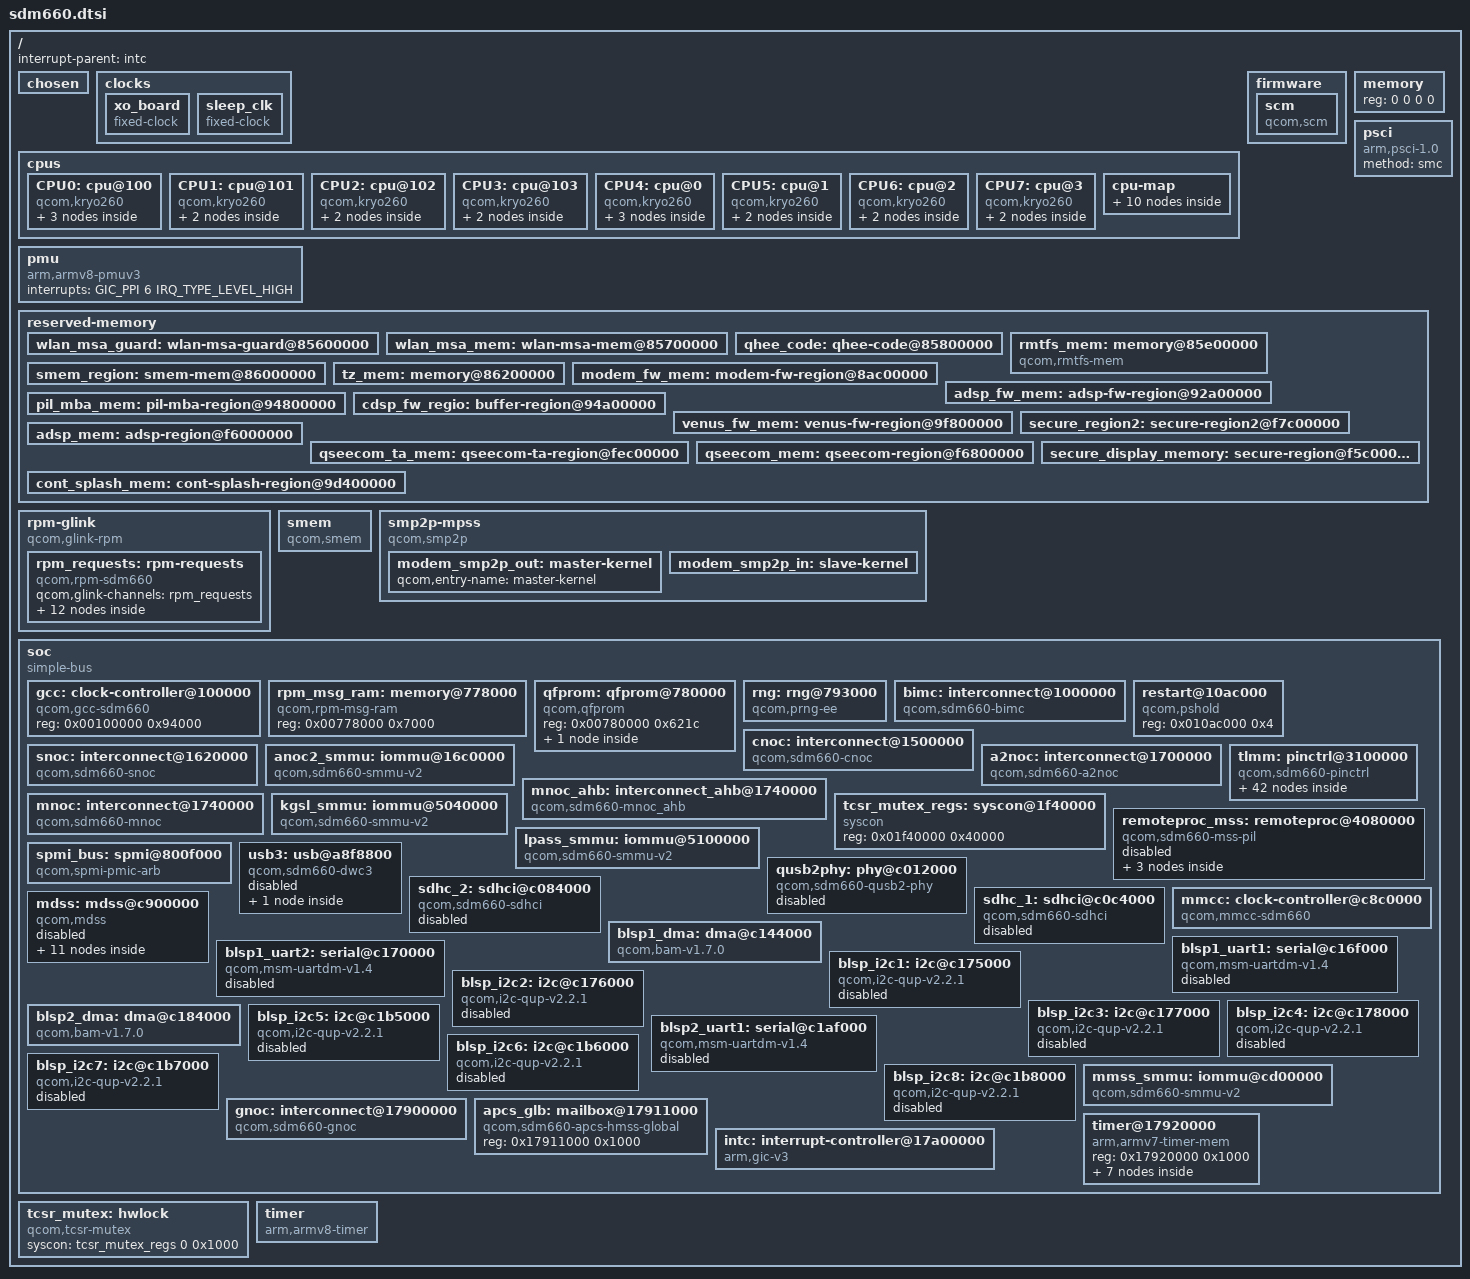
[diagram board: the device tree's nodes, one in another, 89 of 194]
// SPDX-License-Identifier: GPL-2.0-only
/*
 * Copyright (c) 2018, Craig Tatlor.
 * Copyright (c) 2020, Alexey Minnekhanov <alexey.min@gmail.com>
 */

#include <dt-bindings/clock/qcom,gcc-sdm660.h>
#include <dt-bindings/clock/qcom,mmcc-sdm660.h>
#include <dt-bindings/clock/qcom,rpmcc.h>
#include <dt-bindings/power/qcom-rpmpd.h>
#include <dt-bindings/gpio/gpio.h>
#include <dt-bindings/interconnect/qcom,sdm660.h>
#include <dt-bindings/interrupt-controller/arm-gic.h>

/ {
	interrupt-parent = <&intc>;

	#address-cells = <2>;
	#size-cells = <2>;

	chosen { };

	clocks {
		xo_board: xo_board {
			compatible = "fixed-clock";
			#clock-cells = <0>;
			clock-frequency = <19200000>;
			clock-output-names = "xo_board";
		};

		sleep_clk: sleep_clk {
			compatible = "fixed-clock";
			#clock-cells = <0>;
			clock-frequency = <32764>;
			clock-output-names = "sleep_clk";
		};
	};

	cpus {
		#address-cells = <2>;
		#size-cells = <0>;

		CPU0: cpu@100 {
			device_type = "cpu";
			compatible = "qcom,kryo260";
			reg = <0x0 0x100>;
			enable-method = "psci";
			capacity-dmips-mhz = <1024>;
			next-level-cache = <&L2_1>;
			L2_1: l2-cache {
				compatible = "cache";
				cache-level = <2>;
			};
			L1_I_100: l1-icache {
				compatible = "cache";
			};
			L1_D_100: l1-dcache {
				compatible = "cache";
			};
		};

		CPU1: cpu@101 {
			device_type = "cpu";
			compatible = "qcom,kryo260";
			reg = <0x0 0x101>;
			enable-method = "psci";
			capacity-dmips-mhz = <1024>;
			next-level-cache = <&L2_1>;
			L1_I_101: l1-icache {
				compatible = "cache";
			};
			L1_D_101: l1-dcache {
				compatible = "cache";
			};
		};

		CPU2: cpu@102 {
			device_type = "cpu";
			compatible = "qcom,kryo260";
			reg = <0x0 0x102>;
			enable-method = "psci";
			capacity-dmips-mhz = <1024>;
			next-level-cache = <&L2_1>;
			L1_I_102: l1-icache {
				compatible = "cache";
			};
			L1_D_102: l1-dcache {
				compatible = "cache";
			};
		};

		CPU3: cpu@103 {
			device_type = "cpu";
			compatible = "qcom,kryo260";
			reg = <0x0 0x103>;
			enable-method = "psci";
			capacity-dmips-mhz = <1024>;
			next-level-cache = <&L2_1>;
			L1_I_103: l1-icache {
				compatible = "cache";
			};
			L1_D_103: l1-dcache {
				compatible = "cache";
			};
		};

		CPU4: cpu@0 {
			device_type = "cpu";
			compatible = "qcom,kryo260";
			reg = <0x0 0x0>;
			enable-method = "psci";
			capacity-dmips-mhz = <640>;
			next-level-cache = <&L2_0>;
			L2_0: l2-cache {
				compatible = "cache";
				cache-level = <2>;
			};
			L1_I_0: l1-icache {
				compatible = "cache";
			};
			L1_D_0: l1-dcache {
				compatible = "cache";
			};
		};

		CPU5: cpu@1 {
			device_type = "cpu";
			compatible = "qcom,kryo260";
			reg = <0x0 0x1>;
			enable-method = "psci";
			capacity-dmips-mhz = <640>;
			next-level-cache = <&L2_0>;
			L1_I_1: l1-icache {
				compatible = "cache";
			};
			L1_D_1: l1-dcache {
				compatible = "cache";
			};
		};

		CPU6: cpu@2 {
			device_type = "cpu";
			compatible = "qcom,kryo260";
			reg = <0x0 0x2>;
			enable-method = "psci";
			capacity-dmips-mhz = <640>;
			next-level-cache = <&L2_0>;
			L1_I_2: l1-icache {
				compatible = "cache";
			};
			L1_D_2: l1-dcache {
				compatible = "cache";
			};
		};

		CPU7: cpu@3 {
			device_type = "cpu";
			compatible = "qcom,kryo260";
			reg = <0x0 0x3>;
			enable-method = "psci";
			capacity-dmips-mhz = <640>;
			next-level-cache = <&L2_0>;
			L1_I_3: l1-icache {
				compatible = "cache";
			};
			L1_D_3: l1-dcache {
				compatible = "cache";
			};
		};

		cpu-map {
			cluster0 {
				core0 {
					cpu = <&CPU4>;
				};

				core1 {
					cpu = <&CPU5>;
				};

				core2 {
					cpu = <&CPU6>;
				};

				core3 {
					cpu = <&CPU7>;
				};
			};

			cluster1 {
				core0 {
					cpu = <&CPU0>;
				};

				core1 {
					cpu = <&CPU1>;
				};

				core2 {
					cpu = <&CPU2>;
				};

				core3 {
					cpu = <&CPU3>;
				};
			};
		};
	};

	firmware {
		scm {
			compatible = "qcom,scm";
		};
	};

	memory {
		device_type = "memory";
		/* We expect the bootloader to fill in the reg */
		reg = <0 0 0 0>;
	};

	pmu {
		compatible = "arm,armv8-pmuv3";
		interrupts = <GIC_PPI 6 IRQ_TYPE_LEVEL_HIGH>;
	};

	psci {
		compatible = "arm,psci-1.0";
		method = "smc";
	};

	reserved-memory {
		#address-cells = <2>;
		#size-cells = <2>;
		ranges;

		wlan_msa_guard: wlan-msa-guard@85600000 {
			reg = <0x0 0x85600000 0x0 0x100000>;
			no-map;
		};

		wlan_msa_mem: wlan-msa-mem@85700000 {
			reg = <0x0 0x85700000 0x0 0x100000>;
			no-map;
		};

		qhee_code: qhee-code@85800000 {
			reg = <0x0 0x85800000 0x0 0x3700000>;
			no-map;
		};

		rmtfs_mem: memory@85e00000 {
			compatible = "qcom,rmtfs-mem";
			reg = <0x0 0x85e00000 0x0 0x200000>;
			no-map;

			qcom,client-id = <1>;
			qcom,vmid = <15>;
		};

		smem_region: smem-mem@86000000 {
			reg = <0 0x86000000 0 0x200000>;
			no-map;
		};

		tz_mem: memory@86200000 {
			reg = <0x0 0x86200000 0x0 0x3300000>;
			no-map;
		};

		modem_fw_mem: modem-fw-region@8ac00000 {
			reg = <0x0 0x8ac00000 0x0 0x7e00000>;
			no-map;
		};

		adsp_fw_mem: adsp-fw-region@92a00000 {
			reg = <0x0 0x92a00000 0x0 0x1e00000>;
			no-map;
		};

		pil_mba_mem: pil-mba-region@94800000 {
			reg = <0x0 0x94800000 0x0 0x200000>;
			no-map;
		};

		cdsp_fw_regio: buffer-region@94a00000 {
			reg = <0x0 0x94a00000 0x0 0x100000>;
			no-map;
		};

		venus_fw_mem: venus-fw-region@9f800000 {
			reg = <0x0 0x9f800000 0x0 0x800000>;
			no-map;
		};

		secure_region2: secure-region2@f7c00000 {
			reg = <0x0 0xf7c00000 0x0 0x5c00000>;
			no-map;
		};

		adsp_mem: adsp-region@f6000000 {
			reg = <0x0 0xf6000000 0x0 0x800000>;
			no-map;
		};

		qseecom_ta_mem: qseecom-ta-region@fec00000 {
			reg = <0x0 0xfec00000 0x0 0x1000000>;
			no-map;
		};

		qseecom_mem: qseecom-region@f6800000 {
			reg = <0x0 0xf6800000 0x0 0x1400000>;
			no-map;
		};

		secure_display_memory: secure-region@f5c00000 {
			reg = <0x0 0xf5c00000 0x0 0x5c00000>;
			no-map;
		};

		cont_splash_mem: cont-splash-region@9d400000 {
			reg = <0x0 0x9d400000 0x0 0x23ff000>;
			no-map;
		};
	};

	rpm-glink {
		compatible = "qcom,glink-rpm";

		interrupts = <GIC_SPI 168 IRQ_TYPE_EDGE_RISING>;
		qcom,rpm-msg-ram = <&rpm_msg_ram>;
		mboxes = <&apcs_glb 0>;

		rpm_requests: rpm-requests {
			compatible = "qcom,rpm-sdm660";
			qcom,glink-channels = "rpm_requests";

			rpmcc: clock-controller {
				compatible = "qcom,rpmcc-sdm660", "qcom,rpmcc";
				#clock-cells = <1>;
			};

			rpmpd: power-controller {
				compatible = "qcom,sdm660-rpmpd";
				#power-domain-cells = <1>;
				operating-points-v2 = <&rpmpd_opp_table>;

				rpmpd_opp_table: opp-table {
					compatible = "operating-points-v2";

					rpmpd_opp_ret: opp1 {
						opp-level = <16>;
					};

					rpmpd_opp_ret_plus: opp2 {
						opp-level = <32>;
					};

					rpmpd_opp_min_svs: opp3 {
						opp-level = <48>;
					};

					rpmpd_opp_low_svs: opp4 {
						opp-level = <64>;
					};

					rpmpd_opp_svs: opp5 {
						opp-level = <128>;
					};

					rpmpd_opp_svs_plus: opp6 {
						opp-level = <192>;
					};

					rpmpd_opp_nom: opp7 {
						opp-level = <256>;
					};

					rpmpd_opp_nom_plus: opp8 {
						opp-level = <320>;
					};

					rpmpd_opp_turbo: opp9 {
						opp-level = <384>;
					};
				};
			};
		};
	};

	smem: smem {
		compatible = "qcom,smem";
		memory-region = <&smem_region>;
		hwlocks = <&tcsr_mutex 3>;
	};

	smp2p-mpss {
		compatible = "qcom,smp2p";
		qcom,smem = <435>, <428>;
		interrupts = <GIC_SPI 451 IRQ_TYPE_EDGE_RISING>;
		mboxes = <&apcs_glb 14>;
		qcom,local-pid = <0>;
		qcom,remote-pid = <1>;

		modem_smp2p_out: master-kernel {
			qcom,entry-name = "master-kernel";
			#qcom,smem-state-cells = <1>;
		};

		modem_smp2p_in: slave-kernel {
			qcom,entry-name = "slave-kernel";
			interrupt-controller;
			#interrupt-cells = <2>;
		};
	};

	soc: soc {
		#address-cells = <1>;
		#size-cells = <1>;
		ranges = <0 0 0 0xffffffff>;
		compatible = "simple-bus";

		gcc: clock-controller@100000 {
			compatible = "qcom,gcc-sdm660";
			#clock-cells = <1>;
			#reset-cells = <1>;
			#power-domain-cells = <1>;
			reg = <0x00100000 0x94000>;
		};

		rpm_msg_ram: memory@778000 {
			compatible = "qcom,rpm-msg-ram";
			reg = <0x00778000 0x7000>;
		};

		qfprom: qfprom@780000 {
			compatible = "qcom,qfprom";
			reg = <0x00780000 0x621c>;
			#address-cells = <1>;
			#size-cells = <1>;

			qusb2_hstx_trim: hstx-trim@240 {
				reg = <0x240 0x1>;
				bits = <0 4>;
			};
		};

		rng: rng@793000 {
			compatible = "qcom,prng-ee";
			reg = <0x00793000 0x1000>;
			clocks = <&gcc GCC_PRNG_AHB_CLK>;
			clock-names = "core";
		};

		bimc: interconnect@1000000 {
			compatible = "qcom,sdm660-bimc";
			reg = <0x01000000 0x80000>;
			#interconnect-cells = <1>;
			clock-names = "bus", "bus_a";
			clocks = <&rpmcc RPM_SMD_BIMC_CLK>,
				 <&rpmcc RPM_SMD_BIMC_A_CLK>;
		};

		restart@10ac000 {
			compatible = "qcom,pshold";
			reg = <0x010ac000 0x4>;
		};

		cnoc: interconnect@1500000 {
			compatible = "qcom,sdm660-cnoc";
			reg = <0x01500000 0x10000>;
			#interconnect-cells = <1>;
			clock-names = "bus", "bus_a";
			clocks = <&rpmcc RPM_SMD_CNOC_CLK>,
				 <&rpmcc RPM_SMD_CNOC_A_CLK>;
		};

		snoc: interconnect@1620000 {
			compatible = "qcom,sdm660-snoc";
			reg = <0x01620000 0x20000>;
			#interconnect-cells = <1>;
			clock-names = "bus", "bus_a";
			clocks = <&rpmcc RPM_SMD_SNOC_CLK>,
				 <&rpmcc RPM_SMD_SNOC_A_CLK>;
		};

		anoc2_smmu: iommu@16c0000 {
			compatible = "qcom,sdm660-smmu-v2", "qcom,smmu-v2";
			reg = <0x016c0000 0x40000>;
			#iommu-cells = <1>;
			qcom,use-3-lvl-tables;
			qcom,skip-init;

			#global-interrupts = <2>;
			interrupts =
				<GIC_SPI 229 IRQ_TYPE_LEVEL_HIGH>,
				<GIC_SPI 231 IRQ_TYPE_LEVEL_HIGH>,

				<GIC_SPI 373 IRQ_TYPE_LEVEL_HIGH>,
				<GIC_SPI 374 IRQ_TYPE_LEVEL_LOW>,
				<GIC_SPI 375 IRQ_TYPE_LEVEL_LOW>,
				<GIC_SPI 376 IRQ_TYPE_LEVEL_LOW>,
				<GIC_SPI 377 IRQ_TYPE_LEVEL_LOW>,
				<GIC_SPI 378 IRQ_TYPE_LEVEL_LOW>,
				<GIC_SPI 462 IRQ_TYPE_LEVEL_HIGH>,
				<GIC_SPI 463 IRQ_TYPE_LEVEL_HIGH>,
				<GIC_SPI 464 IRQ_TYPE_LEVEL_HIGH>,
				<GIC_SPI 465 IRQ_TYPE_LEVEL_HIGH>,
				<GIC_SPI 466 IRQ_TYPE_LEVEL_HIGH>,
				<GIC_SPI 467 IRQ_TYPE_LEVEL_HIGH>,
				<GIC_SPI 353 IRQ_TYPE_LEVEL_HIGH>,
				<GIC_SPI 354 IRQ_TYPE_LEVEL_HIGH>,
				<GIC_SPI 355 IRQ_TYPE_LEVEL_HIGH>,
				<GIC_SPI 356 IRQ_TYPE_LEVEL_HIGH>,
				<GIC_SPI 357 IRQ_TYPE_LEVEL_HIGH>,
				<GIC_SPI 358 IRQ_TYPE_LEVEL_HIGH>,
				<GIC_SPI 359 IRQ_TYPE_LEVEL_HIGH>,
				<GIC_SPI 360 IRQ_TYPE_LEVEL_HIGH>,
				<GIC_SPI 442 IRQ_TYPE_LEVEL_HIGH>,
				<GIC_SPI 443 IRQ_TYPE_LEVEL_HIGH>,
				<GIC_SPI 444 IRQ_TYPE_LEVEL_HIGH>,
				<GIC_SPI 447 IRQ_TYPE_LEVEL_HIGH>,
				<GIC_SPI 468 IRQ_TYPE_LEVEL_HIGH>,
				<GIC_SPI 469 IRQ_TYPE_LEVEL_HIGH>,
				<GIC_SPI 472 IRQ_TYPE_LEVEL_HIGH>,
				<GIC_SPI 473 IRQ_TYPE_LEVEL_HIGH>,
				<GIC_SPI 474 IRQ_TYPE_LEVEL_HIGH>;
		};

		a2noc: interconnect@1700000 {
			compatible = "qcom,sdm660-a2noc";
			reg = <0x01700000 0x20000>;
			#interconnect-cells = <1>;
			clock-names = "bus", "bus_a";
			clocks = <&rpmcc RPM_SMD_AGGR2_NOC_CLK>,
				 <&rpmcc RPM_SMD_AGGR2_NOC_A_CLK>;
		};

		/*
		 * Having two nodes at the same address with the
		 * same name isn't something DTC agrees with..
		 */
		mnoc_ahb: interconnect_ahb@1740000 {
			compatible = "qcom,sdm660-mnoc_ahb";
			reg = <0x01740000 0x10000>;
			#interconnect-cells = <1>;
			clock-names = "bus", "bus_a";
			clocks = <&mmcc AHB_CLK_SRC>, <&mmcc AHB_CLK_SRC>;
		};

		mnoc: interconnect@1740000 {
			compatible = "qcom,sdm660-mnoc";
			reg = <0x01740000 0x10000>;
			#interconnect-cells = <1>;
			clock-names = "bus", "bus_a";
			clocks = <&rpmcc RPM_SMD_MMSSNOC_AXI_CLK>,
				 <&rpmcc RPM_SMD_MMSSNOC_AXI_CLK_A>;
		};

		tcsr_mutex_regs: syscon@1f40000 {
			compatible = "syscon";
			reg = <0x01f40000 0x40000>;
		};

		tlmm: pinctrl@3100000 {
			compatible = "qcom,sdm660-pinctrl";
			reg = <0x03100000 0x400000>,
			      <0x03500000 0x400000>,
			      <0x03900000 0x400000>;
			reg-names = "south", "center", "north";
			interrupts = <GIC_SPI 208 IRQ_TYPE_LEVEL_HIGH>;
			gpio-controller;
			gpio-ranges = <&tlmm 0 0 114>;
			#gpio-cells = <2>;
			interrupt-controller;
			#interrupt-cells = <2>;

			uart_console_active: uart_console_active {
				pinmux {
					pins = "gpio4", "gpio5";
					function = "blsp_uart2";
				};

				pinconf {
					pins = "gpio4", "gpio5";
					drive-strength = <2>;
					bias-disable;
				};
			};

			blsp1_uart1_default: blsp1-uart1-default {
				pins = "gpio0", "gpio1", "gpio2", "gpio3";
				drive-strength = <2>;
				bias-disable;
			};

			blsp1_uart1_sleep: blsp1-uart1-sleep {
				pins = "gpio0", "gpio1", "gpio2", "gpio3";
				drive-strength = <2>;
				bias-disable;
			};

			blsp1_uart2_default: blsp1-uart2-default {
				pins = "gpio4", "gpio5";
				drive-strength = <2>;
				bias-disable;
			};

			blsp2_uart1_tx_active: blsp2-uart1-tx-active {
				pins = "gpio16";
				drive-strength = <2>;
				bias-disable;
			};

			blsp2_uart1_tx_sleep: blsp2-uart1-tx-sleep {
				pins = "gpio16";
				drive-strength = <2>;
				bias-pull-up;
			};

			blsp2_uart1_rxcts_active: blsp2-uart1-rxcts-active {
				pins = "gpio17", "gpio18";
				drive-strength = <2>;
				bias-disable;
			};

			blsp2_uart1_rxcts_sleep: blsp2-uart1-rxcts-sleep {
				pins = "gpio17", "gpio18";
				drive-strength = <2>;
				bias-no-pull;
			};

			blsp2_uart1_rfr_active: blsp2-uart1-rfr-active {
				pins = "gpio19";
				drive-strength = <2>;
				bias-disable;
			};

			blsp2_uart1_rfr_sleep: blsp2-uart1-rfr-sleep {
				pins = "gpio19";
				drive-strength = <2>;
				bias-no-pull;
			};

			i2c1_default: i2c1-default {
				pins = "gpio2", "gpio3";
				drive-strength = <2>;
				bias-disable;
			};

			i2c1_sleep: i2c1-sleep {
				pins = "gpio2", "gpio3";
				drive-strength = <2>;
				bias-pull-up;
			};

			i2c2_default: i2c2-default {
				pins = "gpio6", "gpio7";
				drive-strength = <2>;
				bias-disable;
			};

			i2c2_sleep: i2c2-sleep {
				pins = "gpio6", "gpio7";
				drive-strength = <2>;
				bias-pull-up;
			};

			i2c3_default: i2c3-default {
				pins = "gpio10", "gpio11";
				drive-strength = <2>;
				bias-disable;
			};

			i2c3_sleep: i2c3-sleep {
				pins = "gpio10", "gpio11";
				drive-strength = <2>;
				bias-pull-up;
			};

			i2c4_default: i2c4-default {
				pins = "gpio14", "gpio15";
				drive-strength = <2>;
				bias-disable;
			};

			i2c4_sleep: i2c4-sleep {
				pins = "gpio14", "gpio15";
				drive-strength = <2>;
				bias-pull-up;
			};

			i2c5_default: i2c5-default {
				pins = "gpio18", "gpio19";
				drive-strength = <2>;
				bias-disable;
			};

			i2c5_sleep: i2c5-sleep {
				pins = "gpio18", "gpio19";
				drive-strength = <2>;
				bias-pull-up;
			};

			i2c6_default: i2c6-default {
				pins = "gpio22", "gpio23";
				drive-strength = <2>;
				bias-disable;
			};

			i2c6_sleep: i2c6-sleep {
				pins = "gpio22", "gpio23";
				drive-strength = <2>;
				bias-pull-up;
			};

			i2c7_default: i2c7-default {
				pins = "gpio26", "gpio27";
				drive-strength = <2>;
				bias-disable;
			};

			i2c7_sleep: i2c7-sleep {
				pins = "gpio26", "gpio27";
				drive-strength = <2>;
				bias-pull-up;
			};

			i2c8_default: i2c8-default {
				pins = "gpio30", "gpio31";
				drive-strength = <2>;
				bias-disable;
			};

			i2c8_sleep: i2c8-sleep {
				pins = "gpio30", "gpio31";
				drive-strength = <2>;
				bias-pull-up;
			};

			sdc1_clk_on: sdc1-clk-on {
				pins = "sdc1_clk";
				bias-disable;
				drive-strength = <16>;
			};

			sdc1_clk_off: sdc1-clk-off {
				pins = "sdc1_clk";
				bias-disable;
				drive-strength = <2>;
			};

			sdc1_cmd_on: sdc1-cmd-on {
				pins = "sdc1_cmd";
				bias-pull-up;
				drive-strength = <10>;
			};

			sdc1_cmd_off: sdc1-cmd-off {
				pins = "sdc1_cmd";
				bias-pull-up;
				drive-strength = <2>;
			};

			sdc1_data_on: sdc1-data-on {
				pins = "sdc1_data";
				bias-pull-up;
				drive-strength = <8>;
			};

			sdc1_data_off: sdc1-data-off {
				pins = "sdc1_data";
				bias-pull-up;
				drive-strength = <2>;
			};

			sdc1_rclk_on: sdc1-rclk-on {
				pins = "sdc1_rclk";
				bias-pull-down;
			};

			sdc1_rclk_off: sdc1-rclk-off {
				pins = "sdc1_rclk";
				bias-pull-down;
			};

			sdc2_clk_on: sdc2-clk-on {
				pins = "sdc2_clk";
				bias-disable;
				drive-strength = <16>;
			};

			sdc2_clk_off: sdc2-clk-off {
				pins = "sdc2_clk";
				bias-disable;
				drive-strength = <2>;
			};

			sdc2_cmd_on: sdc2-cmd-on {
				pins = "sdc2_cmd";
				bias-pull-up;
				drive-strength = <10>;
			};

			sdc2_cmd_off: sdc2-cmd-off {
				pins = "sdc2_cmd";
				bias-pull-up;
				drive-strength = <2>;
			};

			sdc2_data_on: sdc2-data-on {
				pins = "sdc2_data";
				bias-pull-up;
				drive-strength = <10>;
			};

			sdc2_data_off: sdc2-data-off {
				pins = "sdc2_data";
				bias-pull-up;
				drive-strength = <2>;
			};
		};

		remoteproc_mss: remoteproc@4080000 {
			compatible = "qcom,sdm660-mss-pil";
			reg = <0x04080000 0x100>, <0x04180000 0x40>;
			reg-names = "qdsp6", "rmb";
			status = "disabled";

			interrupts-extended =
				<&intc GIC_SPI 448 IRQ_TYPE_EDGE_RISING>,
				<&modem_smp2p_in 0 IRQ_TYPE_EDGE_RISING>,
				<&modem_smp2p_in 1 IRQ_TYPE_EDGE_RISING>,
				<&modem_smp2p_in 2 IRQ_TYPE_EDGE_RISING>,
				<&modem_smp2p_in 3 IRQ_TYPE_EDGE_RISING>,
				<&modem_smp2p_in 7 IRQ_TYPE_EDGE_RISING>;
			interrupt-names = "wdog", "fatal", "ready",
					  "handover", "stop-ack",
					  "shutdown-ack";

			clocks = <&gcc GCC_MSS_CFG_AHB_CLK>,
				 <&gcc GCC_BIMC_MSS_Q6_AXI_CLK>,
				 <&gcc GCC_BOOT_ROM_AHB_CLK>,
				 <&gcc GPLL0_OUT_MSSCC>,
				 <&gcc GCC_MSS_SNOC_AXI_CLK>,
				 <&gcc GCC_MSS_MNOC_BIMC_AXI_CLK>,
				 <&rpmcc RPM_SMD_QDSS_CLK>,
				 <&rpmcc RPM_SMD_XO_CLK_SRC>;
			clock-names = "iface", "bus", "mem", "gpll0_mss",
				      "snoc_axi", "mnoc_axi", "qdss", "xo";

			qcom,smem-states = <&modem_smp2p_out 0>;
			qcom,smem-state-names = "stop";

			resets = <&gcc GCC_MSS_RESTART>;
			reset-names = "mss_restart";

			qcom,halt-regs = <&tcsr_mutex_regs 0x23000 0x25000 0x24000>;

			power-domains = <&rpmpd SDM660_VDDCX>,
					<&rpmpd SDM660_VDDMX>;
			power-domain-names = "cx", "mx";

			mba {
				memory-region = <&pil_mba_mem>;
			};

			mpss {
				memory-region = <&modem_fw_mem>;
			};

			glink-edge {
				interrupts = <GIC_SPI 452 IRQ_TYPE_EDGE_RISING>;
				label = "modem";
				qcom,remote-pid = <1>;
				mboxes = <&apcs_glb 15>;
			};
		};

		kgsl_smmu: iommu@5040000 {
			compatible = "qcom,sdm660-smmu-v2", "qcom,smmu-v2";
			reg = <0x05040000 0x10000>;
			#iommu-cells = <1>;
			qcom,use-3-lvl-tables;
			qcom,skip-init;

			interrupts =
				<GIC_SPI 329 IRQ_TYPE_LEVEL_HIGH>,
				<GIC_SPI 330 IRQ_TYPE_LEVEL_HIGH>,
				<GIC_SPI 331 IRQ_TYPE_LEVEL_HIGH>,
				<GIC_SPI 332 IRQ_TYPE_LEVEL_HIGH>,
				<GIC_SPI 116 IRQ_TYPE_LEVEL_HIGH>;
		};

		lpass_smmu: iommu@5100000 {
			compatible = "qcom,sdm660-smmu-v2", "qcom,smmu-v2";
			reg = <0x05100000 0x40000>;
			#iommu-cells = <1>;
			qcom,use-3-lvl-tables;
			qcom,skip-init;

			#global-interrupts = <2>;
			interrupts =
				<GIC_SPI 229 IRQ_TYPE_LEVEL_HIGH>,
				<GIC_SPI 231 IRQ_TYPE_LEVEL_HIGH>,

				<GIC_SPI 226 IRQ_TYPE_LEVEL_HIGH>,
				<GIC_SPI 393 IRQ_TYPE_LEVEL_HIGH>,
				<GIC_SPI 394 IRQ_TYPE_LEVEL_HIGH>,
				<GIC_SPI 395 IRQ_TYPE_LEVEL_HIGH>,
				<GIC_SPI 396 IRQ_TYPE_LEVEL_HIGH>,
				<GIC_SPI 397 IRQ_TYPE_LEVEL_HIGH>,
				<GIC_SPI 398 IRQ_TYPE_LEVEL_HIGH>,
				<GIC_SPI 399 IRQ_TYPE_LEVEL_HIGH>,
				<GIC_SPI 400 IRQ_TYPE_LEVEL_HIGH>,
				<GIC_SPI 401 IRQ_TYPE_LEVEL_HIGH>,
				<GIC_SPI 402 IRQ_TYPE_LEVEL_HIGH>,
				<GIC_SPI 403 IRQ_TYPE_LEVEL_HIGH>,
				<GIC_SPI 137 IRQ_TYPE_LEVEL_HIGH>,
				<GIC_SPI 224 IRQ_TYPE_LEVEL_HIGH>,
				<GIC_SPI 225 IRQ_TYPE_LEVEL_HIGH>,
				<GIC_SPI 310 IRQ_TYPE_LEVEL_HIGH>,
				<GIC_SPI 404 IRQ_TYPE_LEVEL_HIGH>;
		};

		spmi_bus: spmi@800f000 {
			compatible = "qcom,spmi-pmic-arb";
			reg = <0x0800f000 0x1000>,
			      <0x08400000 0x1000000>,
			      <0x09400000 0x1000000>,
			      <0x0a400000 0x220000>,
			      <0x0800a000 0x3000>;
			reg-names = "core", "chnls", "obsrvr", "intr", "cnfg";
			interrupt-names = "periph_irq";
			interrupts = <GIC_SPI 326 IRQ_TYPE_LEVEL_HIGH>;
			qcom,ee = <0>;
			qcom,channel = <0>;
			#address-cells = <2>;
			#size-cells = <0>;
			interrupt-controller;
			#interrupt-cells = <4>;
			cell-index = <0>;
		};

		usb3: usb@a8f8800 {
			compatible = "qcom,sdm660-dwc3", "qcom,dwc3";
			reg = <0x0a8f8800 0x400>;
			status = "disabled";
			#address-cells = <1>;
			#size-cells = <1>;
			ranges;

			clocks = <&gcc GCC_CFG_NOC_USB3_AXI_CLK>,
				 <&gcc GCC_USB30_MASTER_CLK>,
				 <&gcc GCC_AGGRE2_USB3_AXI_CLK>,
				 <&gcc GCC_USB30_MOCK_UTMI_CLK>,
				 <&gcc GCC_USB30_SLEEP_CLK>;
			clock-names = "cfg_noc", "core", "iface", "mock_utmi",
				      "sleep";

			assigned-clocks = <&gcc GCC_USB30_MOCK_UTMI_CLK>,
					  <&gcc GCC_USB30_MASTER_CLK>;
			assigned-clock-rates = <19200000>, <120000000>;

			interrupts = <GIC_SPI 347 IRQ_TYPE_LEVEL_HIGH>,
				     <GIC_SPI 243 IRQ_TYPE_LEVEL_HIGH>;
			interrupt-names = "hs_phy_irq", "ss_phy_irq";

			power-domains = <&gcc USB_30_GDSC>;
			qcom,select-utmi-as-pipe-clk;

			resets = <&gcc GCC_USB_30_BCR>;

			usb3_dwc3: dwc3@a800000 {
				compatible = "snps,dwc3";
				reg = <0x0a800000 0xc8d0>;
				interrupts = <GIC_SPI 131 IRQ_TYPE_LEVEL_HIGH>;
				snps,dis_u2_susphy_quirk;
				snps,dis_enblslpm_quirk;

				/*
				 * SDM660 technically supports USB3 but I
				 * haven't seen any devices making use of it.
				 */
				maximum-speed = "high-speed";
				phys = <&qusb2phy>;
				phy-names = "usb2-phy";
				snps,hird-threshold = /bits/ 8 <0>;
			};
		};

		qusb2phy: phy@c012000 {
			compatible = "qcom,sdm660-qusb2-phy";
			reg = <0x0c012000 0x180>;
			#phy-cells = <0>;

			clocks = <&gcc GCC_USB_PHY_CFG_AHB2PHY_CLK>,
				<&gcc GCC_RX1_USB2_CLKREF_CLK>;
			clock-names = "cfg_ahb", "ref";

			resets = <&gcc GCC_QUSB2PHY_PRIM_BCR>;
			nvmem-cells = <&qusb2_hstx_trim>;
			status = "disabled";
		};

		sdhc_2: sdhci@c084000 {
			compatible = "qcom,sdm660-sdhci", "qcom,sdhci-msm-v5";
			reg = <0x0c084000 0x1000>;
			reg-names = "hc";

			interrupts = <GIC_SPI 125 IRQ_TYPE_LEVEL_HIGH>,
					<GIC_SPI 221 IRQ_TYPE_LEVEL_HIGH>;
			interrupt-names = "hc_irq", "pwr_irq";

			clocks = <&gcc GCC_SDCC2_APPS_CLK>,
					<&gcc GCC_SDCC2_AHB_CLK>,
					<&xo_board>;
			clock-names = "core", "iface", "xo";

			pinctrl-names = "default", "sleep";
			pinctrl-0 = <&sdc2_clk_on &sdc2_cmd_on &sdc2_data_on>;
			pinctrl-1 = <&sdc2_clk_off &sdc2_cmd_off &sdc2_data_off>;

			bus-width = <4>;
			interconnects = <&a2noc MASTER_SDCC_2 &bimc SLAVE_EBI>,
				<&gnoc MASTER_APSS_PROC  &cnoc SLAVE_SDCC_2>;

			status = "disabled";
		};

		sdhc_1: sdhci@c0c4000 {
			compatible = "qcom,sdm660-sdhci", "qcom,sdhci-msm-v5";
			reg = <0x0c0c4000 0x1000>,
				<0x0c0c5000 0x1000>;
			reg-names = "hc", "cqhci";

			interrupts = <GIC_SPI 110 IRQ_TYPE_LEVEL_HIGH>,
					<GIC_SPI 112 IRQ_TYPE_LEVEL_HIGH>;
			interrupt-names = "hc_irq", "pwr_irq";

			clocks = <&gcc GCC_SDCC1_APPS_CLK>,
					<&gcc GCC_SDCC1_AHB_CLK>,
					<&xo_board>;
			clock-names = "core", "iface", "xo";

			pinctrl-names = "default", "sleep";
			pinctrl-0 = <&sdc1_clk_on &sdc1_cmd_on &sdc1_data_on &sdc1_rclk_on>;
			pinctrl-1 = <&sdc1_clk_off &sdc1_cmd_off &sdc1_data_off &sdc1_rclk_off>;

			bus-width = <8>;
			non-removable;

			status = "disabled";
		};

		mmcc: clock-controller@c8c0000 {
			compatible = "qcom,mmcc-sdm660";
			reg = <0x0c8c0000 0x40000>;
			#clock-cells = <1>;
			#reset-cells = <1>;
			#power-domain-cells = <1>;
			clock-names = "xo",
					"sleep_clk",
					"gpll0",
					"gpll0_div",
					"dsi0pll",
					"dsi0pllbyte",
					"dsi1pll",
					"dsi1pllbyte",
					"dp_link_2x_clk_divsel_five",
					"dp_vco_divided_clk_src_mux";
			clocks = <&rpmcc RPM_SMD_XO_CLK_SRC>,
					<&sleep_clk>,
					<&gcc GCC_MMSS_GPLL0_CLK>,
					<&gcc GCC_MMSS_GPLL0_DIV_CLK>,
					<&dsi0_phy 1>,
					<&dsi0_phy 0>,
					<0>,
					<0>,
					<0>,
					<0>;
		};

		mdss: mdss@c900000 {
			compatible = "qcom,mdss";
			reg = <0x0c900000 0x1000>,
			      <0x0c9b0000 0x1040>;
			reg-names = "mdss_phys", "vbif_phys";

			power-domains = <&mmcc MDSS_GDSC>;

			clocks = <&mmcc MDSS_AHB_CLK>,
				 <&mmcc MDSS_AXI_CLK>,
				 <&mmcc MDSS_VSYNC_CLK>,
				 <&mmcc MDSS_MDP_CLK>;
			clock-names = "iface",
				      "bus",
				      "vsync",
					  "core";

			interrupts = <GIC_SPI 83 IRQ_TYPE_LEVEL_HIGH>;

			interrupt-controller;
			#interrupt-cells = <1>;

			#address-cells = <1>;
			#size-cells = <1>;
			ranges;
			status = "disabled";

			mdp: mdp@c901000 {
				compatible = "qcom,mdp5";
				reg = <0x0c901000 0x89000>;
				reg-names = "mdp_phys";

				interrupt-parent = <&mdss>;
				interrupts = <0 IRQ_TYPE_LEVEL_HIGH>;

				power-domains = <&mmcc MDSS_GDSC>;

				clocks = <&mmcc MDSS_AHB_CLK>,
					 <&mmcc MDSS_AXI_CLK>,
					 <&mmcc MDSS_MDP_CLK>,
					 <&mmcc MDSS_VSYNC_CLK>;
				clock-names = "iface",
					      "bus",
					      "core",
					      "vsync";

				iommus = <&mmss_smmu 0>;

				ports {
					#address-cells = <1>;
					#size-cells = <0>;

					port@0 {
						reg = <0>;
						mdp5_intf1_out: endpoint {
							remote-endpoint = <&dsi0_in>;
						};
					};
				};
			};

			dsi0: dsi@c994000 {
				compatible = "qcom,mdss-dsi-ctrl";
				reg = <0x0c994000 0x400>;
				reg-names = "dsi_ctrl";
				power-domains = <&mmcc MDSS_GDSC>;

				interrupt-parent = <&mdss>;
				interrupts = <4 0>;

				assigned-clocks = <&mmcc BYTE0_CLK_SRC>,
						  <&mmcc PCLK0_CLK_SRC>;
				assigned-clock-parents = <&dsi0_phy 0>,
							 <&dsi0_phy 1>;

				clocks = <&mmcc MDSS_MDP_CLK>,
					 <&mmcc MDSS_BYTE0_INTF_CLK>,
					 <&mmcc MNOC_AHB_CLK>,
					 <&mmcc MDSS_AHB_CLK>,
					 <&mmcc MDSS_AXI_CLK>,
					 <&mmcc MISC_AHB_CLK>,
					 <&mmcc MDSS_BYTE0_CLK>,
					 <&mmcc MDSS_PCLK0_CLK>,
					 <&mmcc MDSS_ESC0_CLK>;
				clock-names = "mdp_core",
					      "byte_intf",
					      "mnoc",
					      "iface",
					      "bus",
					      "core_mmss",
					      "byte",
					      "pixel",
					      "core";

				phys = <&dsi0_phy>;
				phy-names = "dsi";

				ports {
					#address-cells = <1>;
					#size-cells = <0>;

					port@0 {
						reg = <0>;
						dsi0_in: endpoint {
							remote-endpoint = <&mdp5_intf1_out>;
						};
					};

					port@1 {
						reg = <1>;
						dsi0_out: endpoint {
						};
					};
				};
			};

			dsi0_phy: dsi-phy@c994400 {
				compatible = "qcom,dsi-phy-14nm-660";
				
				reg = <0x0c994400 0x100>,
				      <0x0c994500 0x300>,
				      <0x0c994800 0x188>;
				reg-names = "dsi_phy",
					    "dsi_phy_lane",
					    "dsi_pll";

				#clock-cells = <1>;
				#phy-cells = <0>;

				clocks = <&mmcc MDSS_AHB_CLK>, <&xo_board>;
				clock-names = "iface", "ref";
			};
		};

		blsp1_dma: dma@c144000 {
			compatible = "qcom,bam-v1.7.0";
			reg = <0x0c144000 0x1f000>;
			interrupts = <GIC_SPI 238 IRQ_TYPE_LEVEL_HIGH>;
			clocks = <&gcc GCC_BLSP1_AHB_CLK>;
			clock-names = "bam_clk";
			#dma-cells = <1>;
			qcom,ee = <0>;
			qcom,controlled-remotely;
			num-channels = <18>;
			qcom,num-ees = <4>;
		};

		blsp1_uart1: serial@c16f000 {
			compatible = "qcom,msm-uartdm-v1.4", "qcom,msm-uartdm";
			reg = <0x0c16f000 0x200>;
			interrupts = <GIC_SPI 107 IRQ_TYPE_LEVEL_HIGH>;
			clocks = <&gcc GCC_BLSP1_UART1_APPS_CLK>,
				 <&gcc GCC_BLSP1_AHB_CLK>;
			clock-names = "core", "iface";
			dmas = <&blsp1_dma 0>, <&blsp1_dma 1>;
			dma-names = "tx", "rx";
			pinctrl-names = "default", "sleep";
			pinctrl-0 = <&blsp1_uart1_default>;
			pinctrl-1 = <&blsp1_uart1_sleep>;
			status = "disabled";
		};

		blsp1_uart2: serial@c170000 {
			compatible = "qcom,msm-uartdm-v1.4", "qcom,msm-uartdm";
			reg = <0x0c170000 0x1000>;
			interrupts = <GIC_SPI 108 IRQ_TYPE_LEVEL_HIGH>;
			clocks = <&gcc GCC_BLSP1_UART2_APPS_CLK>,
				 <&gcc GCC_BLSP1_AHB_CLK>;
			clock-names = "core", "iface";
			status = "disabled";
		};

		blsp_i2c1: i2c@c175000 {
			compatible = "qcom,i2c-qup-v2.2.1";
			reg = <0x0c175000 0x600>;
			interrupts = <GIC_SPI 95 IRQ_TYPE_LEVEL_HIGH>;

			clocks = <&gcc GCC_BLSP1_QUP1_I2C_APPS_CLK>,
					<&gcc GCC_BLSP1_AHB_CLK>;
			clock-names = "core", "iface";
			clock-frequency = <400000>;

			pinctrl-names = "default", "sleep";
			pinctrl-0 = <&i2c1_default>;
			pinctrl-1 = <&i2c1_sleep>;
			#address-cells = <1>;
			#size-cells = <0>;
			status = "disabled";
		};

		blsp_i2c2: i2c@c176000 {
			compatible = "qcom,i2c-qup-v2.2.1";
			reg = <0x0c176000 0x600>;
			interrupts = <GIC_SPI 96 IRQ_TYPE_LEVEL_HIGH>;

			clocks = <&gcc GCC_BLSP1_QUP2_I2C_APPS_CLK>,
				 <&gcc GCC_BLSP1_AHB_CLK>;
			clock-names = "core", "iface";
			clock-frequency = <400000>;

			pinctrl-names = "default", "sleep";
			pinctrl-0 = <&i2c2_default>;
			pinctrl-1 = <&i2c2_sleep>;
			#address-cells = <1>;
			#size-cells = <0>;
			status = "disabled";
		};

		blsp_i2c3: i2c@c177000 {
			compatible = "qcom,i2c-qup-v2.2.1";
			reg = <0x0c177000 0x600>;
			interrupts = <GIC_SPI 97 IRQ_TYPE_LEVEL_HIGH>;

			clocks = <&gcc GCC_BLSP1_QUP3_I2C_APPS_CLK>,
				 <&gcc GCC_BLSP1_AHB_CLK>;
			clock-names = "core", "iface";
			clock-frequency = <400000>;

			pinctrl-names = "default", "sleep";
			pinctrl-0 = <&i2c3_default>;
			pinctrl-1 = <&i2c3_sleep>;
			#address-cells = <1>;
			#size-cells = <0>;
			status = "disabled";
		};

		blsp_i2c4: i2c@c178000 {
			compatible = "qcom,i2c-qup-v2.2.1";
			reg = <0x0c178000 0x600>;
			interrupts = <GIC_SPI 98 IRQ_TYPE_LEVEL_HIGH>;

			clocks = <&gcc GCC_BLSP1_QUP4_I2C_APPS_CLK>,
				 <&gcc GCC_BLSP1_AHB_CLK>;
			clock-names = "core", "iface";
			clock-frequency = <400000>;

			pinctrl-names = "default", "sleep";
			pinctrl-0 = <&i2c4_default>;
			pinctrl-1 = <&i2c4_sleep>;
			#address-cells = <1>;
			#size-cells = <0>;
			status = "disabled";
		};

		blsp2_dma: dma@c184000 {
			compatible = "qcom,bam-v1.7.0";
			reg = <0x0c184000 0x1f000>;
			interrupts = <GIC_SPI 239 IRQ_TYPE_LEVEL_HIGH>;
			clocks = <&gcc GCC_BLSP2_AHB_CLK>;
			clock-names = "bam_clk";
			#dma-cells = <1>;
			qcom,ee = <0>;
			qcom,controlled-remotely;
			num-channels = <18>;
			qcom,num-ees = <4>;
		};

		blsp2_uart1: serial@c1af000 {
			compatible = "qcom,msm-uartdm-v1.4", "qcom,msm-uartdm";
			reg = <0x0c1af000 0x200>;
			interrupts = <GIC_SPI 113 IRQ_TYPE_LEVEL_HIGH>;
			clocks = <&gcc GCC_BLSP2_UART1_APPS_CLK>,
				 <&gcc GCC_BLSP2_AHB_CLK>;
			clock-names = "core", "iface";
			dmas = <&blsp2_dma 0>, <&blsp2_dma 1>;
			dma-names = "tx", "rx";
			pinctrl-names = "default", "sleep";
			pinctrl-0 = <&blsp2_uart1_tx_active &blsp2_uart1_rxcts_active
				&blsp2_uart1_rfr_active>;
			pinctrl-1 = <&blsp2_uart1_tx_sleep &blsp2_uart1_rxcts_sleep
				&blsp2_uart1_rfr_sleep>;
			status = "disabled";
		};

		blsp_i2c5: i2c@c1b5000 {
			compatible = "qcom,i2c-qup-v2.2.1";
			reg = <0x0c1b5000 0x600>;
			interrupts = <GIC_SPI 101 IRQ_TYPE_LEVEL_HIGH>;

			clocks = <&gcc GCC_BLSP2_QUP1_I2C_APPS_CLK>,
				 <&gcc GCC_BLSP2_AHB_CLK>;
			clock-names = "core", "iface";
			clock-frequency = <400000>;

			pinctrl-names = "default", "sleep";
			pinctrl-0 = <&i2c5_default>;
			pinctrl-1 = <&i2c5_sleep>;
			#address-cells = <1>;
			#size-cells = <0>;
			status = "disabled";
		};

		blsp_i2c6: i2c@c1b6000 {
			compatible = "qcom,i2c-qup-v2.2.1";
			reg = <0x0c1b6000 0x600>;
			interrupts = <GIC_SPI 102 IRQ_TYPE_LEVEL_HIGH>;

			clocks = <&gcc GCC_BLSP2_QUP2_I2C_APPS_CLK>,
				 <&gcc GCC_BLSP2_AHB_CLK>;
			clock-names = "core", "iface";
			clock-frequency = <400000>;

			pinctrl-names = "default", "sleep";
			pinctrl-0 = <&i2c6_default>;
			pinctrl-1 = <&i2c6_sleep>;
			#address-cells = <1>;
			#size-cells = <0>;
			status = "disabled";
		};

		blsp_i2c7: i2c@c1b7000 {
			compatible = "qcom,i2c-qup-v2.2.1";
			reg = <0x0c1b7000 0x600>;
			interrupts = <GIC_SPI 103 IRQ_TYPE_LEVEL_HIGH>;

			clocks = <&gcc GCC_BLSP2_QUP3_I2C_APPS_CLK>,
				 <&gcc GCC_BLSP2_AHB_CLK>;
			clock-names = "core", "iface";
			clock-frequency = <400000>;

			pinctrl-names = "default", "sleep";
			pinctrl-0 = <&i2c7_default>;
			pinctrl-1 = <&i2c7_sleep>;
			#address-cells = <1>;
			#size-cells = <0>;
			status = "disabled";
		};

		blsp_i2c8: i2c@c1b8000 {
			compatible = "qcom,i2c-qup-v2.2.1";
			reg = <0x0c1b8000 0x600>;
			interrupts = <GIC_SPI 104 IRQ_TYPE_LEVEL_HIGH>;

			clocks = <&gcc GCC_BLSP2_QUP4_I2C_APPS_CLK>,
				 <&gcc GCC_BLSP2_AHB_CLK>;
			clock-names = "core", "iface";
			clock-frequency = <400000>;

			pinctrl-names = "default", "sleep";
			pinctrl-0 = <&i2c8_default>;
			pinctrl-1 = <&i2c8_sleep>;
			#address-cells = <1>;
			#size-cells = <0>;
			status = "disabled";
		};

		mmss_smmu: iommu@cd00000 {
			compatible = "qcom,sdm660-smmu-v2", "qcom,smmu-v2";
			reg = <0x0cd00000 0x40000>;
			#iommu-cells = <1>;
			qcom,use-3-lvl-tables;
			qcom,skip-init;
			qcom,no-smr-check;

			#global-interrupts = <2>;
			interrupts =
				<GIC_SPI 229 IRQ_TYPE_LEVEL_HIGH>,
				<GIC_SPI 231 IRQ_TYPE_LEVEL_HIGH>,

				<GIC_SPI 263 IRQ_TYPE_LEVEL_HIGH>,
				<GIC_SPI 266 IRQ_TYPE_LEVEL_HIGH>,
				<GIC_SPI 267 IRQ_TYPE_LEVEL_HIGH>,
				<GIC_SPI 268 IRQ_TYPE_LEVEL_HIGH>,
				<GIC_SPI 244 IRQ_TYPE_LEVEL_HIGH>,
				<GIC_SPI 245 IRQ_TYPE_LEVEL_HIGH>,
				<GIC_SPI 247 IRQ_TYPE_LEVEL_HIGH>,
				<GIC_SPI 248 IRQ_TYPE_LEVEL_HIGH>,
				<GIC_SPI 249 IRQ_TYPE_LEVEL_HIGH>,
				<GIC_SPI 250 IRQ_TYPE_LEVEL_HIGH>,
				<GIC_SPI 251 IRQ_TYPE_LEVEL_HIGH>,
				<GIC_SPI 252 IRQ_TYPE_LEVEL_HIGH>,
				<GIC_SPI 253 IRQ_TYPE_LEVEL_HIGH>,
				<GIC_SPI 254 IRQ_TYPE_LEVEL_HIGH>,
				<GIC_SPI 255 IRQ_TYPE_LEVEL_HIGH>,
				<GIC_SPI 256 IRQ_TYPE_LEVEL_HIGH>,
				<GIC_SPI 260 IRQ_TYPE_LEVEL_HIGH>,
				<GIC_SPI 261 IRQ_TYPE_LEVEL_HIGH>,
				<GIC_SPI 262 IRQ_TYPE_LEVEL_HIGH>,
				<GIC_SPI 272 IRQ_TYPE_LEVEL_HIGH>,
				<GIC_SPI 273 IRQ_TYPE_LEVEL_HIGH>,
				<GIC_SPI 274 IRQ_TYPE_LEVEL_HIGH>,
				<GIC_SPI 275 IRQ_TYPE_LEVEL_HIGH>,
				<GIC_SPI 276 IRQ_TYPE_LEVEL_HIGH>;

			clocks = <&mmcc BIMC_SMMU_AHB_CLK>,
						<&mmcc BIMC_SMMU_AXI_CLK>;
			clock-names = "iface", "bus";
		};

		gnoc: interconnect@17900000 {
			compatible = "qcom,sdm660-gnoc";
			reg = <0x17900000 0xe000>;
			#interconnect-cells = <1>;
			/*
			 * This one apparently features no clocks,
			 * so let's not mess with the driver needlessly
			 */
			clock-names = "bus", "bus_a";
			clocks = <&xo_board>, <&xo_board>;
		};

		apcs_glb: mailbox@17911000 {
			compatible = "qcom,sdm660-apcs-hmss-global";
			reg = <0x17911000 0x1000>;

			#mbox-cells = <1>;
		};

		timer@17920000 {
			#address-cells = <1>;
			#size-cells = <1>;
			ranges;
			compatible = "arm,armv7-timer-mem";
			reg = <0x17920000 0x1000>;

			frame@17921000 {
				frame-number = <0>;
				interrupts = <GIC_SPI 8 IRQ_TYPE_LEVEL_HIGH>,
					     <GIC_SPI 7 IRQ_TYPE_LEVEL_HIGH>;
				reg = <0x17921000 0x1000>,
				      <0x17922000 0x1000>;
			};

			frame@17923000 {
				frame-number = <1>;
				interrupts = <GIC_SPI 9 IRQ_TYPE_LEVEL_HIGH>;
				reg = <0x17923000 0x1000>;
				status = "disabled";
			};

			frame@17924000 {
				frame-number = <2>;
				interrupts = <GIC_SPI 10 IRQ_TYPE_LEVEL_HIGH>;
				reg = <0x17924000 0x1000>;
				status = "disabled";
			};

			frame@17925000 {
				frame-number = <3>;
				interrupts = <GIC_SPI 11 IRQ_TYPE_LEVEL_HIGH>;
				reg = <0x17925000 0x1000>;
				status = "disabled";
			};

			frame@17926000 {
				frame-number = <4>;
				interrupts = <GIC_SPI 12 IRQ_TYPE_LEVEL_HIGH>;
				reg = <0x17926000 0x1000>;
				status = "disabled";
			};

			frame@17927000 {
				frame-number = <5>;
				interrupts = <GIC_SPI 13 IRQ_TYPE_LEVEL_HIGH>;
				reg = <0x17927000 0x1000>;
				status = "disabled";
			};

			frame@17928000 {
				frame-number = <6>;
				interrupts = <GIC_SPI 14 IRQ_TYPE_LEVEL_HIGH>;
				reg = <0x17928000 0x1000>;
				status = "disabled";
			};
		};

		intc: interrupt-controller@17a00000 {
			compatible = "arm,gic-v3";
			reg = <0x17a00000 0x10000>,
			      <0x17b00000 0x100000>;
			#interrupt-cells = <3>;
			#address-cells = <1>;
			#size-cells = <1>;
			ranges;
			interrupt-controller;
			#redistributor-regions = <1>;
			redistributor-stride = <0x0 0x20000>;
			interrupts = <GIC_PPI 9 IRQ_TYPE_LEVEL_HIGH>;
		};
	};

	tcsr_mutex: hwlock {
		compatible = "qcom,tcsr-mutex";
		syscon = <&tcsr_mutex_regs 0 0x1000>;
		#hwlock-cells = <1>;
	};

	timer {
		compatible = "arm,armv8-timer";
		interrupts = <GIC_PPI 1 IRQ_TYPE_LEVEL_LOW>,
			     <GIC_PPI 2 IRQ_TYPE_LEVEL_LOW>,
			     <GIC_PPI 3 IRQ_TYPE_LEVEL_LOW>,
			     <GIC_PPI 0 IRQ_TYPE_LEVEL_LOW>;
	};
};
